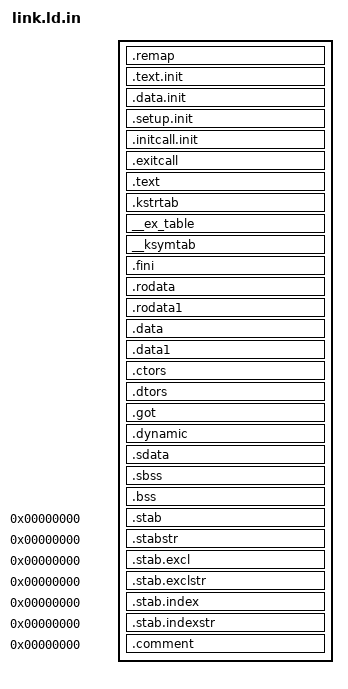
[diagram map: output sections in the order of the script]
OUTPUT_FORMAT("elf32-ELF_SUBARCH")
OUTPUT_ARCH(ELF_SUBARCH)
ENTRY(_start)

SECTIONS
{
  . = START() + SIZEOF_HEADERS;
  .remap : { arch/um/kernel/unmap_fin.o (.text) }

  . = ALIGN(4096);		/* Init code and data */
  _stext = .;
  __init_begin = .;
  .text.init : { *(.text.init) }
  .data.init : { *(.data.init) }
  . = ALIGN(16);
  __setup_start = .;
  .setup.init : { *(.setup.init) }
  __setup_end = .;
  __initcall_start = .;
  .initcall.init : { *(.initcall.init) }
  __initcall_end = .;
  . = ALIGN(4096);
  __init_end = .;
  __exitcall_begin = .;
  .exitcall : { *(.exitcall.exit) }
  __exitcall_end = .;

  .text      :
  {
    *(.text)
    /* .gnu.warning sections are handled specially by elf32.em.  */
    *(.gnu.warning)
    *(.gnu.linkonce.t*)
  } =0x9090
  .kstrtab : { *(.kstrtab) }

  . = ALIGN(16);		/* Exception table */
  __start___ex_table = .;
  __ex_table : { *(__ex_table) }
  __stop___ex_table = .;

  __start___ksymtab = .;	/* Kernel symbol table */
  __ksymtab : { *(__ksymtab) }
  __stop___ksymtab = .;
  .fini      : { *(.fini)    } =0x9090
  .rodata    : { *(.rodata) *(.gnu.linkonce.r*) }
  .rodata1   : { *(.rodata1) }
  _etext = .;
  PROVIDE (etext = .);
  /* Adjust the address for the data segment.  We want to adjust up to
     the same address within the page on the next page up.  */
  . = ALIGN(0x1000) + (. & (0x1000 - 1));
  .data    :
  {
    _sdata = .;
    PROVIDE (sdata = .);
    . = ALIGN(16384);		/* init_task */
    *(.data.init_task)
    *(.data)
    *(.gnu.linkonce.d*)
    CONSTRUCTORS
  }
  .data1   : { *(.data1) }
  .ctors         :
  {
    *(.ctors)
  }
  .dtors         :
  {
    *(.dtors)
  }

  .got           : { *(.got.plt) *(.got) }
  .dynamic       : { *(.dynamic) }
  /* We want the small data sections together, so single-instruction offsets
     can access them all, and initialized data all before uninitialized, so
     we can shorten the on-disk segment size.  */
  .sdata     : { *(.sdata) }
  _edata  =  .;
  PROVIDE (edata = .);
  . = ALIGN(0x1000);
  .sbss      : 
  {
   __bss_start = .;
   PROVIDE(_bss_start = .);
   *(.sbss) 
   *(.scommon) 
  }
  .bss       :
  {
   *(.dynbss)
   *(.bss)
   *(COMMON)
  }
  _end = . ;
  PROVIDE (end = .);
  /* Stabs debugging sections.  */
  .stab 0 : { *(.stab) }
  .stabstr 0 : { *(.stabstr) }
  .stab.excl 0 : { *(.stab.excl) }
  .stab.exclstr 0 : { *(.stab.exclstr) }
  .stab.index 0 : { *(.stab.index) }
  .stab.indexstr 0 : { *(.stab.indexstr) }
  .comment 0 : { *(.comment) }
}
